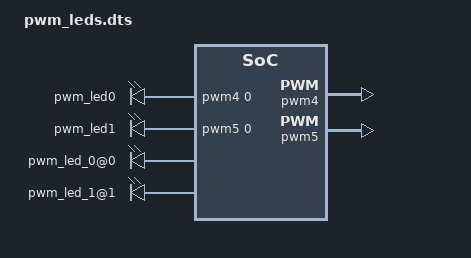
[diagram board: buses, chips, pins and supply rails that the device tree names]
/* Copyright 2022 The Chromium OS Authors. All rights reserved.
 * Use of this source code is governed by a BSD-style license that can be
 * found in the LICENSE file.
 */

/ {
	pwmleds {
		compatible = "pwm-leds";
		pwm_led0: pwm_led_0 {
			pwms = <&pwm4 0 0 PWM_POLARITY_INVERTED>;
		};
		pwm_led1: pwm_led_1 {
			pwms = <&pwm5 0 0 PWM_POLARITY_INVERTED>;
		};
	};

	cros-pwmleds {
		compatible = "cros-ec,pwm-leds";

		leds = <&pwm_led0 &pwm_led1>;
		frequency = <4800>;

				/*<on   off>*/
		color-map-red    = <0    0>;
		color-map-green  = <100  0>;
		color-map-blue   = <0    0>;
		color-map-yellow = <0    0>;
		color-map-white  = <0    0>;
		color-map-amber  = <0    0>;

		brightness-range = <0 100 0 0 0 0>;


		#address-cells = <1>;
		#size-cells = <0>;

		pwm_led_0@0 {
			reg = <0>;
			ec-led-name = "EC_LED_ID_BATTERY_LED";
		};

		pwm_led_1@1 {
			reg = <1>;
			ec-led-name = "EC_LED_ID_POWER_LED";
		};
	};
};

/* LED1 */
&pwm4 {
	status = "okay";
	clock-bus = "NPCX_CLOCK_BUS_LFCLK";
};

/* LED2 */
&pwm5 {
	status = "okay";
	clock-bus = "NPCX_CLOCK_BUS_LFCLK";
};
